# NV32F100 register map
File version: 1.6
Registers are 32-bit, read-write, reset 0x0 unless marked. A register's access mark holds for its fields unless they carry their own. Offsets are from the block's base; [hi:lo] are bit positions; {n}, {i} and the like mark numbered series.

## CMP0 — High-Speed Comparator (CMP), Voltage Reference (VREF) Digital-to-Analog Converter (DAC), and Analog Mux (ANMUX)
Base 0x40073000; register names take the prefix CMP0_
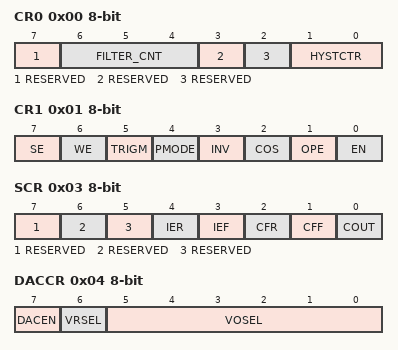
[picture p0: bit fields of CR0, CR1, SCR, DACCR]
0x00 CR0 8-bit — CMP Control Register 0
  [7] RESERVED ro
  [6:4] FILTER_CNT — Filter Sample Count
    0=Filter is disabled. If SE = 1, then COUT is a logic 0. This is not a legal state, and is not recommended. If SE = 0, COUT = COUTA.; 1=One sample must agree. The comparator output is simply sampled.; {v}={v} consecutive samples must agree (v=2..7)
  [3] RESERVED ro
  [2] RESERVED ro
  [1:0] HYSTCTR — Comparator hard block hysteresis control
    {v}=Level {v} (v=0..3)
0x01 CR1 8-bit — CMP Control Register 1
  [7] SE — Sample Enable
    0=Sampling mode is not selected; 1=Sampling mode is selected
  [6] WE — Windowing Enable
    0=Windowing mode is not selected; 1=Windowing mode is selected
  [5] TRIGM — Trigger Mode Enable
    0=Trigger mode is disabled; 1=Trigger mode is enabled
  [4] PMODE — Power Mode Select
    0=Low-Speed (LS) Comparison mode selected. In this mode, CMP has slower output propagation delay and lower current consumption.; 1=High-Speed (HS) Comparison mode selected. In this mode, CMP has faster output propagation delay and higher current consumption.
  [3] INV — Comparator INVERT
    0=Does not invert the comparator output; 1=Inverts the comparator output
  [2] COS — Comparator Output Select
    0=Set the filtered comparator output (CMPO) to equal COUT; 1=Set the unfiltered comparator output (CMPO) to equal COUTA
  [1] OPE — Comparator Output Pin Enable
    0=CMPO is not available on the associated CMPO output pin. If the comparator does not own the pin, this field has no effect.; 1=CMPO is available on the associated CMPO output pin. The comparator output (CMPO) is driven out on the associated CMPO output pin if the comparator owns the pin. If the comparator does not own the field, this bit has no effect.
  [0] EN — Comparator Module Enable
    0=Analog Comparator is disabled; 1=Analog Comparator is enabled
0x02 FPR 8-bit — CMP Filter Period Register
  [7:0] FILT_PER — Filter Sample Period
0x03 SCR 8-bit — CMP Status and Control Register
  [7] RESERVED ro
  [6] RESERVED
  [5] RESERVED ro
  [4] IER — Comparator Interrupt Enable Rising
    0=Interrupt is disabled; 1=Interrupt is enabled
  [3] IEF — Comparator Interrupt Enable Falling
    0=Interrupt is disabled; 1=Interrupt is enabled
  [2] CFR — Analog Comparator Flag Rising
    0=Rising-edge on COUT has not been detected; 1=Rising-edge on COUT has occurred
  [1] CFF — Analog Comparator Flag Falling
    0=Falling-edge on COUT has not been detected; 1=Falling-edge on COUT has occurred
  [0] COUT ro — Analog Comparator Output
0x04 DACCR 8-bit — DAC Control Register
  [7] DACEN — DAC Enable
    0=DAC is disabled; 1=DAC is enabled
  [6] VRSEL — Supply Voltage Reference Source Select
    0=V is selected as resistor ladder network supply reference V. in1 in; 1=V is selected as resistor ladder network supply reference V. in2 in
  [5:0] VOSEL — DAC Output Voltage Select
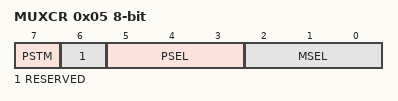
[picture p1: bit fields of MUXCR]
0x05 MUXCR 8-bit — MUX Control Register
  [7] PSTM — Pass Through Mode Enable
    0=Pass Through Mode is disabled; 1=Pass Through Mode is enabled
  [6] RESERVED ro
  [5:3] PSEL — Plus Input Mux Control
    {v}=IN{v} (v=0..7)
  [2:0] MSEL — Minus Input Mux Control
    {v}=IN{v} (v=0..7)

## PMC — Power Management Controller
Base 0x4007D000; register names take the prefix PMC_
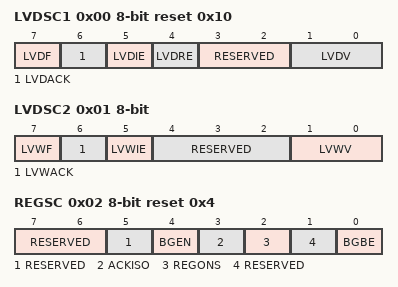
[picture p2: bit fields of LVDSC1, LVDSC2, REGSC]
0x00 LVDSC1 8-bit reset 0x10 — Low Voltage Detect Status And Control 1 register
  [7] LVDF ro — Low-Voltage Detect Flag
    0=Low-voltage event not detected; 1=Low-voltage event detected
  [6] LVDACK wo — Low-Voltage Detect Acknowledge
  [5] LVDIE — Low-Voltage Detect Interrupt Enable
    0=Hardware interrupt disabled (use polling); 1=Request a hardware interrupt when LVDF = 1
  [4] LVDRE — Low-Voltage Detect Reset Enable
    0=LVDF does not generate hardware resets; 1=Force an MCU reset when LVDF = 1
  [3:2] RESERVED ro
  [1:0] LVDV — Low-Voltage Detect Voltage Select
    0=Low trip point selected (V LVD = V LVDL ); 1=High trip point selected (V LVD = V LVDH )
0x01 LVDSC2 8-bit — Low Voltage Detect Status And Control 2 register
  [7] LVWF ro — Low-Voltage Warning Flag
    0=Low-voltage warning event not detected; 1=Low-voltage warning event detected
  [6] LVWACK wo — Low-Voltage Warning Acknowledge
  [5] LVWIE — Low-Voltage Warning Interrupt Enable
    0=Hardware interrupt disabled (use polling); 1=Request a hardware interrupt when LVWF = 1
  [4:2] RESERVED ro
  [1:0] LVWV — Low-Voltage Warning Voltage Select
    0=Low trip point selected (VLVW = VLVW1); 1=Mid 1 trip point selected (VLVW = VLVW2); 2=Mid 2 trip point selected (VLVW = VLVW3); 3=High trip point selected (VLVW = VLVW4)
0x02 REGSC 8-bit reset 0x4 — Regulator Status And Control register
  [7:6] RESERVED ro
  [5] RESERVED
  [4] BGEN — Bandgap Enable In VLPx Operation
    0=Bandgap voltage reference is disabled in VLPx , and VLLSx modes; 1=Bandgap voltage reference is enabled in VLPx , and VLLSx modes
  [3] ACKISO — Acknowledge Isolation
    0=Peripherals and I/O pads are in normal run state; 1=Certain peripherals and I/O pads are in an isolated and latched state
  [2] REGONS ro — Regulator In Run Regulation Status
    0=Regulator is in stop regulation or in transition to/from it; 1=Regulator is in run regulation
  [1] RESERVED
  [0] BGBE — Bandgap Buffer Enable
    0=Bandgap buffer not enabled; 1=Bandgap buffer enabled
